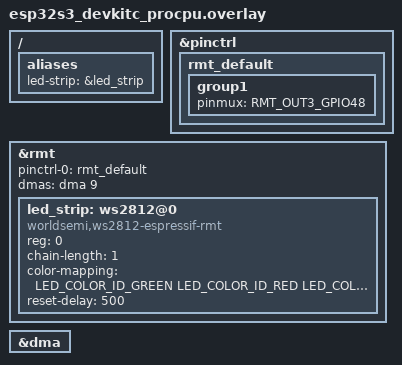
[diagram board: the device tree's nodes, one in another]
/*
 * Copyright (c) 2024-2025 Espressif Systems (Shanghai) Co., Ltd.
 *
 * SPDX-License-Identifier: Apache-2.0
 */

#include <zephyr/dt-bindings/led/led.h>

/delete-node/ &rmt_default;

/ {
	aliases {
		led-strip = &led_strip;
	};
};

&pinctrl {
	rmt_default: rmt_default {
		group1 {
			pinmux = <RMT_OUT3_GPIO48>;
		};
	};
};

&rmt {
	status = "okay";
	pinctrl-0 = <&rmt_default>;
	pinctrl-names = "default";
	dmas = <&dma 9>;
	dma-names = "tx";

	led_strip: ws2812@0 {
		compatible = "worldsemi,ws2812-espressif-rmt";
		reg = <0>;
		chain-length = <1>;
		color-mapping = <LED_COLOR_ID_GREEN
				 LED_COLOR_ID_RED
				 LED_COLOR_ID_BLUE>;
		reset-delay = <500>;
	};
};

&dma {
	status = "okay";
};
